AUTOSAR XML (schema 3-2-1)
package /SeatHeater/SeatHeater_swc
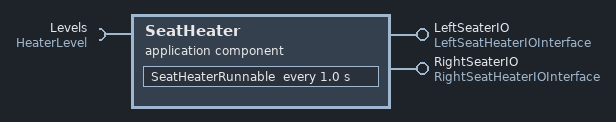
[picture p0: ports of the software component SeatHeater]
  application software component type SeatHeater
    require port Levels: provided-com-specs=[{data-element=LeftHeatLevel, alive-timeout=60.0}, {data-element=RightHeatLevel, alive-timeout=60.0}], provided-interface=HeaterLevel
    provide port LeftSeaterIO: unqueued-provider-com-spec{data-element=LeftHeaterValue, alive-timeout=60.0}, provided-interface=LeftSeatHeaterIOInterface
    provide port RightSeaterIO: unqueued-provider-com-spec{data-element=RightHeaterValue, alive-timeout=60.0}, provided-interface=RightSeatHeaterIOInterface
  internal behavior SeatHeaterBehavior: component=SeatHeater
    timing event SeatHeaterEvent: start-on-event=SeatHeaterRunnable, period=1.0
    runnable SeatHeaterRunnable: can-be-invoked-concurrently=true
      data read access SeatHeaterLeftLevelAccess: data-element=Levels.LeftHeatLevel
      data read access SeatHeaterRightLevelAccess: data-element=Levels.RightHeatLevel
      data write access SeatHeaterLeftIOAccess: data-element=LeftSeaterIO.LeftHeaterValue
      data write access SeatHeaterRightIOAccess: data-element=RightSeaterIO.RightHeaterValue
  swc implementation SeatHeaterImplementation: behavior=SeatHeaterBehavior
